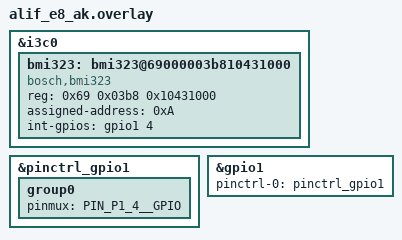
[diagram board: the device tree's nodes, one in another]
/*
 * Copyright (c) 2025 Alif Semiconductor.
 * SPDX-License-Identifier: Apache-2.0
 */

&i3c0 {
	status = "okay";

	bmi323: bmi323@69000003b810431000 {
		compatible = "bosch,bmi323";
		reg = <0x69 0x03b8 0x10431000>;
		/* Dynamic Address To Be Assigned To The Device */
		assigned-address = <0xA>;
		int-gpios	 = <&gpio1 4 GPIO_ACTIVE_HIGH>;
		status		 = "okay";
	};
};

&pinctrl_gpio1 {
	group0 {
		/* Enable only Port-1 Pin-4 */
		pinmux = <PIN_P1_4__GPIO>;
	};
};

&gpio1 {
	pinctrl-0	= <&pinctrl_gpio1>;
	pinctrl-names	= "default";
	status		= "okay";
};
